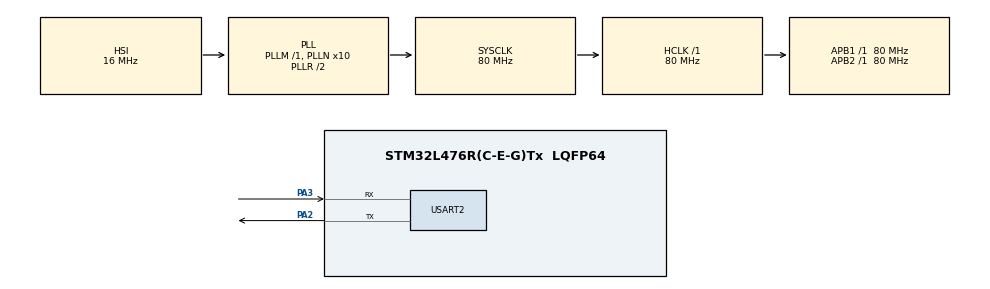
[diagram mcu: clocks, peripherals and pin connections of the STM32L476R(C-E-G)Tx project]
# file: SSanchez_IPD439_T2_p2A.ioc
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FREERTOS.Queues01=FIFO_Queue,100,uint32_t,0,Dynamic,NULL,NULL
FREERTOS.Tasks01=defaultTask,24,128,StartDefaultTask,Default,NULL,Dynamic,NULL,NULL;myTask,24,256,Media_y_desv,As external,NULL,Dynamic,NULL,NULL
FREERTOS.configUSE_NEWLIB_REENTRANT=1
Mcu.Family=STM32L4
Mcu.Name=STM32L476R(C-E-G)Tx
Mcu.Package=LQFP64
NVIC.PriorityGroup=NVIC_PRIORITYGROUP_4
NVIC.USART2_IRQn=true\:5\:0\:false\:false\:true\:true\:true\:true\:true
PA2.Mode=Asynchronous
PA2.Signal=USART2_TX
PA3.Mode=Asynchronous
PA3.Signal=USART2_RX
ProjectManager.HeapSize=0x200
ProjectManager.StackSize=0x400
ProjectManager.TargetToolchain=STM32CubeIDE
RCC.ADCFreq_Value=64000000
RCC.AHBFreq_Value=80000000
RCC.APB1Freq_Value=80000000
RCC.APB1TimFreq_Value=80000000
RCC.APB2Freq_Value=80000000
RCC.APB2TimFreq_Value=80000000
RCC.CortexFreq_Value=80000000
RCC.HCLKFreq_Value=80000000
RCC.HSE_VALUE=8000000
RCC.HSI_VALUE=16000000
RCC.LSE_VALUE=32768
RCC.MSI_VALUE=4000000
RCC.PLLN=10
RCC.PLLSourceVirtual=RCC_PLLSOURCE_HSI
RCC.SYSCLKFreq_VALUE=80000000
RCC.SYSCLKSource=RCC_SYSCLKSOURCE_PLLCLK
RCC.USBFreq_Value=64000000
RCC.VCOOutputFreq_Value=160000000
USART2.VirtualMode-Asynchronous=VM_ASYNC
VP_FREERTOS_VS_CMSIS_V2.Mode=CMSIS_V2
board=custom

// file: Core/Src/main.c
/* USER CODE BEGIN Header */
/**
  ******************************************************************************
  * @file           : main.c
  * @brief          : Main program body
  ******************************************************************************
  * @attention
  *
  * Copyright (c) 2026 STMicroelectronics.
  * All rights reserved.
  *
  * This software is licensed under terms that can be found in the LICENSE file
  * in the root directory of this software component.
  * If no LICENSE file comes with this software, it is provided AS-IS.
  *
  ******************************************************************************
  */
/* USER CODE END Header */
#include "main.h"
#include "cmsis_os.h"
#include "usart.h"
#include "gpio.h"

/* USER CODE BEGIN Includes */
#include "funciones.h"
/* USER CODE END Includes */

/* USER CODE BEGIN PV */
volatile uint8_t rx_byte;
/* USER CODE END PV */

void SystemClock_Config(void);
void MX_FREERTOS_Init(void);

int main(void)
{

  /* MCU Configuration--------------------------------------------------------*/

  /* Reset of all peripherals, Initializes the Flash interface and the Systick. */
  HAL_Init();

  /* Configure the system clock */
  SystemClock_Config();

  /* Initialize all configured peripherals */
  MX_GPIO_Init();
  MX_USART2_UART_Init();
  /* USER CODE BEGIN 2 */

    //activar la interrupción por USART
   HAL_UART_Receive_IT(&huart2, &rx_byte, 1);

  /* USER CODE END 2 */

  /* Init scheduler */
  osKernelInitialize();  /* Call init function for freertos objects (in freertos.c) */
  MX_FREERTOS_Init();

  /* Start scheduler */
  osKernelStart();

  /* We should never get here as control is now taken by the scheduler */
  /* Infinite loop */
  while (1)
  {

  }
}

void SystemClock_Config(void)
{
  RCC_OscInitTypeDef RCC_OscInitStruct = {0};
  RCC_ClkInitTypeDef RCC_ClkInitStruct = {0};

  /** Configure the main internal regulator output voltage
  */
  if (HAL_PWREx_ControlVoltageScaling(PWR_REGULATOR_VOLTAGE_SCALE1) != HAL_OK)
  {
    Error_Handler();
  }

  /** Initializes the RCC Oscillators according to the specified parameters
  * in the RCC_OscInitTypeDef structure.
  */
  RCC_OscInitStruct.OscillatorType = RCC_OSCILLATORTYPE_HSI;
  RCC_OscInitStruct.HSIState = RCC_HSI_ON;
  RCC_OscInitStruct.HSICalibrationValue = RCC_HSICALIBRATION_DEFAULT;
  RCC_OscInitStruct.PLL.PLLState = RCC_PLL_ON;
  RCC_OscInitStruct.PLL.PLLSource = RCC_PLLSOURCE_HSI;
  RCC_OscInitStruct.PLL.PLLM = 1;
  RCC_OscInitStruct.PLL.PLLN = 10;
  RCC_OscInitStruct.PLL.PLLP = RCC_PLLP_DIV7;
  RCC_OscInitStruct.PLL.PLLQ = RCC_PLLQ_DIV2;
  RCC_OscInitStruct.PLL.PLLR = RCC_PLLR_DIV2;
  if (HAL_RCC_OscConfig(&RCC_OscInitStruct) != HAL_OK)
  {
    Error_Handler();
  }

  /** Initializes the CPU, AHB and APB buses clocks
  */
  RCC_ClkInitStruct.ClockType = RCC_CLOCKTYPE_HCLK|RCC_CLOCKTYPE_SYSCLK
                              |RCC_CLOCKTYPE_PCLK1|RCC_CLOCKTYPE_PCLK2;
  RCC_ClkInitStruct.SYSCLKSource = RCC_SYSCLKSOURCE_PLLCLK;
  RCC_ClkInitStruct.AHBCLKDivider = RCC_SYSCLK_DIV1;
  RCC_ClkInitStruct.APB1CLKDivider = RCC_HCLK_DIV1;
  RCC_ClkInitStruct.APB2CLKDivider = RCC_HCLK_DIV1;

  if (HAL_RCC_ClockConfig(&RCC_ClkInitStruct, FLASH_LATENCY_4) != HAL_OK)
  {
    Error_Handler();
  }
}

void Error_Handler(void)
{
  __disable_irq();
  while (1)
  {
  }
}

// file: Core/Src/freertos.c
/* USER CODE BEGIN Header */
/**
  ******************************************************************************
  * File Name          : freertos.c
  * Description        : Code for freertos applications
  ******************************************************************************
  * @attention
  *
  * Copyright (c) 2026 STMicroelectronics.
  * All rights reserved.
  *
  * This software is licensed under terms that can be found in the LICENSE file
  * in the root directory of this software component.
  * If no LICENSE file comes with this software, it is provided AS-IS.
  *
  ******************************************************************************
  */
/* USER CODE END Header */

#include "FreeRTOS.h"
#include "task.h"
#include "main.h"
#include "cmsis_os.h"

/* Definitions for defaultTask */
osThreadId_t defaultTaskHandle;
const osThreadAttr_t defaultTask_attributes = {
  .name = "defaultTask",
  .stack_size = 128 * 4,
  .priority = (osPriority_t) osPriorityNormal,
};
/* Definitions for myTask */
osThreadId_t myTaskHandle;
const osThreadAttr_t myTask_attributes = {
  .name = "myTask",
  .stack_size = 256 * 4,
  .priority = (osPriority_t) osPriorityNormal,
};
/* Definitions for FIFO_Queue */
osMessageQueueId_t FIFO_QueueHandle;
const osMessageQueueAttr_t FIFO_Queue_attributes = {
  .name = "FIFO_Queue"
};

void StartDefaultTask(void *argument);
extern void Media_y_desv(void *argument);

void MX_FREERTOS_Init(void); /* (MISRA C 2004 rule 8.1) */

void MX_FREERTOS_Init(void) {

  /* Create the queue(s) */
  /* creation of FIFO_Queue */
  FIFO_QueueHandle = osMessageQueueNew (100, sizeof(uint32_t), &FIFO_Queue_attributes);

  /* Create the thread(s) */
  /* creation of defaultTask */
  defaultTaskHandle = osThreadNew(StartDefaultTask, NULL, &defaultTask_attributes);

  /* creation of myTask */
  myTaskHandle = osThreadNew(Media_y_desv, NULL, &myTask_attributes);

}

void StartDefaultTask(void *argument)
{
  for(;;)
  {
    osDelay(1);
  }
}
